VERSION ""

NS_ :

BS_:

BU_: PI_EVCC

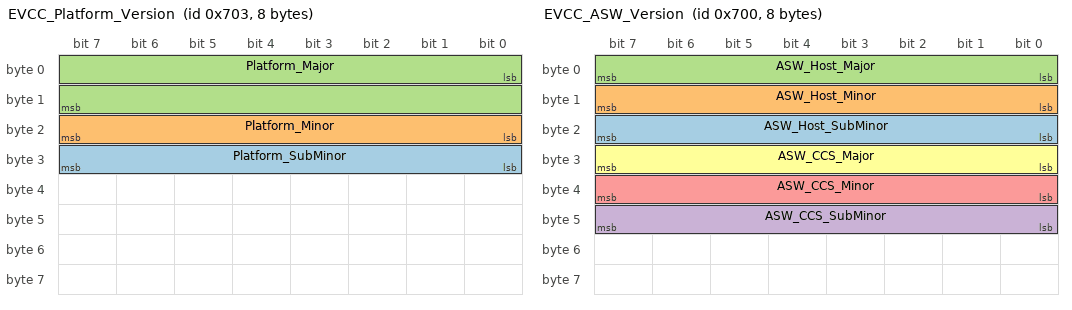
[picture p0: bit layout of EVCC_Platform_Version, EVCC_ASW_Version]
BO_ 1795 EVCC_Platform_Version: 8 PI_EVCC
 SG_ Platform_SubMinor : 24|8@1+ (1,0) [0|0] "" Vector__XXX
 SG_ Platform_Minor : 16|8@1+ (1,0) [0|0] "" Vector__XXX
 SG_ Platform_Major : 0|16@1+ (1,0) [0|0] "" Vector__XXX

BO_ 1792 EVCC_ASW_Version: 8 PI_EVCC
 SG_ ASW_Host_SubMinor : 16|8@1+ (1,0) [0|0] "" Vector__XXX
 SG_ ASW_Host_Minor : 8|8@1+ (1,0) [0|0] "" Vector__XXX
 SG_ ASW_Host_Major : 0|8@1+ (1,0) [0|0] "" Vector__XXX
 SG_ ASW_CCS_SubMinor : 40|8@1+ (1,0) [0|0] "" Vector__XXX
 SG_ ASW_CCS_Minor : 32|8@1+ (1,0) [0|0] "" Vector__XXX
 SG_ ASW_CCS_Major : 24|8@1+ (1,0) [0|0] "" Vector__XXX

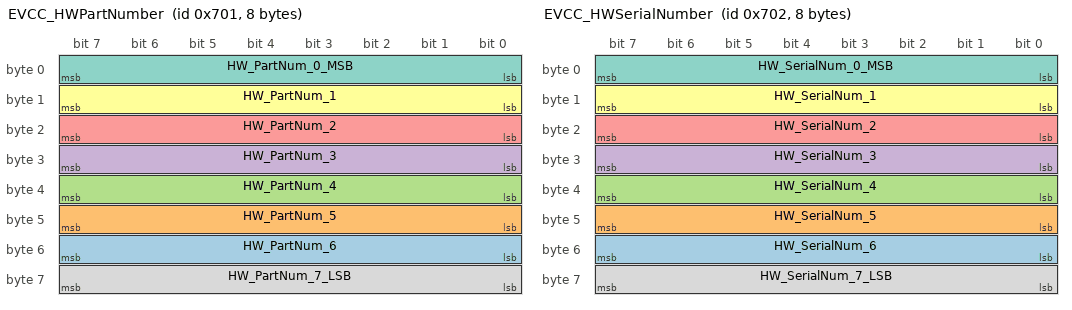
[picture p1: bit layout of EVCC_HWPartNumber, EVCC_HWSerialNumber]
BO_ 1793 EVCC_HWPartNumber: 8 PI_EVCC
 SG_ HW_PartNum_6 : 48|8@1+ (1,0) [0|0] "" Vector__XXX
 SG_ HW_PartNum_5 : 40|8@1+ (1,0) [0|0] "" Vector__XXX
 SG_ HW_PartNum_4 : 32|8@1+ (1,0) [0|0] "" Vector__XXX
 SG_ HW_PartNum_3 : 24|8@1+ (1,0) [0|0] "" Vector__XXX
 SG_ HW_PartNum_2 : 16|8@1+ (1,0) [0|0] "" Vector__XXX
 SG_ HW_PartNum_1 : 8|8@1+ (1,0) [0|0] "" Vector__XXX
 SG_ HW_PartNum_0_MSB : 0|8@1+ (1,0) [0|0] "" Vector__XXX
 SG_ HW_PartNum_7_LSB : 56|8@1+ (1,0) [0|0] "" Vector__XXX

BO_ 1794 EVCC_HWSerialNumber: 8 PI_EVCC
 SG_ HW_SerialNum_6 : 48|8@1+ (1,0) [0|0] "" Vector__XXX
 SG_ HW_SerialNum_5 : 40|8@1+ (1,0) [0|0] "" Vector__XXX
 SG_ HW_SerialNum_4 : 32|8@1+ (1,0) [0|0] "" Vector__XXX
 SG_ HW_SerialNum_3 : 24|8@1+ (1,0) [0|0] "" Vector__XXX
 SG_ HW_SerialNum_2 : 16|8@1+ (1,0) [0|0] "" Vector__XXX
 SG_ HW_SerialNum_1 : 8|8@1+ (1,0) [0|0] "" Vector__XXX
 SG_ HW_SerialNum_0_MSB : 0|8@1+ (1,0) [0|0] "" Vector__XXX
 SG_ HW_SerialNum_7_LSB : 56|8@1+ (1,0) [0|0] "" Vector__XXX

BA_DEF_ SG_  "SigType" ENUM  "Default","Range","RangeSigned","ASCII","Discrete","Control","ReferencePGN","DTC","StringDelimiter","StringLength","StringLengthControl","MessageCounter","MessageChecksum";
BA_DEF_ SG_  "GenSigEVName" STRING ;
BA_DEF_ SG_  "GenSigILSupport" ENUM  "No","Yes";
BA_DEF_ SG_  "GenSigSendType" ENUM  "Cyclic","OnWrite","OnWriteWithRepetition","OnChange","OnChangeWithRepetition","IfActive","IfActiveWithRepetition","NoSigSendType";
BA_DEF_ BO_  "GenMsgILSupport" ENUM  "No","Yes";
BA_DEF_ BU_  "NmStationAddress" INT 0 255;
BA_DEF_ BO_  "GenMsgSendType" ENUM  "cyclic","NotUsed","IfActive","NotUsed","NotUsed","NotUsed","NotUsed","NotUsed","noMsgSendType";
BA_DEF_ BO_  "GenMsgRequestable" INT 0 1;
BA_DEF_ BO_  "GenMsgCycleTime" INT 0 3600000;
BA_DEF_  "DBName" STRING ;
BA_DEF_  "BusType" STRING ;
BA_DEF_  "ProtocolType" STRING ;
BA_DEF_ BO_  "VFrameFormat" ENUM  "StandardCAN","ExtendedCAN","reserved","J1939PG";
BA_DEF_DEF_  "SigType" "Default";
BA_DEF_DEF_  "GenSigEVName" "Env@Nodename_@Signame";
BA_DEF_DEF_  "GenSigILSupport" "Yes";
BA_DEF_DEF_  "GenSigSendType" "NoSigSendType";
BA_DEF_DEF_  "GenMsgILSupport" "Yes";
BA_DEF_DEF_  "NmStationAddress" 254;
BA_DEF_DEF_  "GenMsgSendType" "noMsgSendType";
BA_DEF_DEF_  "GenMsgRequestable" 1;
BA_DEF_DEF_  "GenMsgCycleTime" 0;
BA_DEF_DEF_  "DBName" "";
BA_DEF_DEF_  "BusType" "CAN";
BA_DEF_DEF_  "ProtocolType" "J1939";
BA_DEF_DEF_  "VFrameFormat" "J1939PG";
BA_ "DBName" "PiEVCC_VehicleBus";
BA_ "NmStationAddress" BU_ PI_EVCC 73;
BA_ "GenMsgCycleTime" BO_ 1795 1000;
BA_ "VFrameFormat" BO_ 1795 0;
BA_ "GenMsgCycleTime" BO_ 1792 1000;
BA_ "VFrameFormat" BO_ 1792 0;
BA_ "GenMsgCycleTime" BO_ 1793 1000;
BA_ "VFrameFormat" BO_ 1793 0;
BA_ "GenMsgCycleTime" BO_ 1794 1000;
BA_ "VFrameFormat" BO_ 1794 0;
